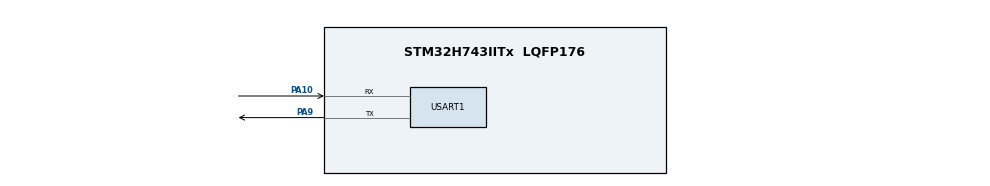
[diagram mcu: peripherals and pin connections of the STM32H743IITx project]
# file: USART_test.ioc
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Mcu.Family=STM32H7
Mcu.Name=STM32H743IITx
Mcu.Package=LQFP176
NVIC.PriorityGroup=NVIC_PRIORITYGROUP_4
NVIC.USART1_IRQn=true\:0\:0\:false\:false\:true\:true\:true
PA10.Mode=Asynchronous
PA10.Signal=USART1_RX
PA9.GPIO_Speed=GPIO_SPEED_FREQ_HIGH
PA9.Mode=Asynchronous
PA9.Signal=USART1_TX
PH0-OSC_IN\ (PH0).Mode=HSE-External-Oscillator
PH0-OSC_IN\ (PH0).Signal=RCC_OSC_IN
PH1-OSC_OUT\ (PH1).Mode=HSE-External-Oscillator
PH1-OSC_OUT\ (PH1).Signal=RCC_OSC_OUT
ProjectManager.HeapSize=0x200
ProjectManager.StackSize=0x400
ProjectManager.TargetToolchain=MDK-ARM V5.27
RCC.ADCFreq_Value=129000000
RCC.APB1Freq_Value=72000000
RCC.APB2Freq_Value=72000000
RCC.APB3Freq_Value=72000000
RCC.APB4Freq_Value=72000000
RCC.CortexFreq_Value=144000000
RCC.DIVM1=4
RCC.DIVN1=18
RCC.HCLKFreq_Value=72000000
RCC.HPRE=RCC_HCLK_DIV2
RCC.PLL2FRACN=0
RCC.PLL3FRACN=0
RCC.PLLFRACN=0
RCC.SYSCLKFreq_VALUE=144000000
RCC.SYSCLKSource=RCC_SYSCLKSOURCE_PLLCLK
RCC.USBFreq_Value=144000000
USART1.VirtualMode-Asynchronous=VM_ASYNC
board=custom

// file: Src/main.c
/* USER CODE BEGIN Header */
/**
  ******************************************************************************
  * @file           : main.c
  * @brief          : Main program body
  ******************************************************************************
  * @attention
  *
  * <h2><center>&copy; Copyright (c) 2020 STMicroelectronics.
  * All rights reserved.</center></h2>
  *
  * This software component is licensed by ST under BSD 3-Clause license,
  * the "License"; You may not use this file except in compliance with the
  * License. You may obtain a copy of the License at:
  *                        opensource.org/licenses/BSD-3-Clause
  *
  ******************************************************************************
  */
/* USER CODE END Header */

#include "main.h"
#include "usart.h"
#include "gpio.h"

/* USER CODE BEGIN PD */
//#define RX_MAX_COUNT           255  // 串口接收最大字节数

/* USER CODE END PD */

/* USER CODE BEGIN PV */
__IO uint8_t aRxBuffer; // 接收缓冲区
//__IO uint8_t aRxBuffer[RX_MAX_COUNT]={0}; //接收缓冲区
//__IO uint16_t usRxcount=0;                  // 已接收到的字节数
//__IO uint8_t Rxflag=0;                //接收标志位
/* USER CODE END PV */

void SystemClock_Config(void);

int main(void)
{
  /* USER CODE BEGIN 1 */
	uint8_t txbuf[100];//发送缓冲区

  /* USER CODE END 1 */

  /* MCU Configuration--------------------------------------------------------*/

  /* Reset of all peripherals, Initializes the Flash interface and the Systick. */
  HAL_Init();

  /* Configure the system clock */
  SystemClock_Config();

  /* Initialize all configured peripherals */
  MX_GPIO_Init();
  MX_USART1_UART_Init();
  /* USER CODE BEGIN 2 */
	memcpy(txbuf,"这是一个从STM32发送到电脑的数据\n",100);// 复制"这是一个从STM32发送到电脑的数据\n"到txbuf
	HAL_UART_Transmit(&huart1,txbuf,strlen((char *) txbuf),1000);// 串口发送函数
	HAL_Delay(1000);

	memcpy(txbuf,"hello world！man！\n",100);// 复制"hello world！man！\n"到txbuf ，100代表要发送的数据。
	HAL_UART_Transmit(&huart1,txbuf,strlen((char *) txbuf),1000);

	//使能接收中断
	HAL_UART_Receive_IT(&huart1,&aRxBuffer,1); //接收到一个数据就会产生中断

  /* USER CODE END 2 */

  /* Infinite loop */
  while (1)
  {

  }
}

//函数功能：串口接收完成回调函数
void HAL_UART_RxCpltCallback(UART_HandleTypeDef *UartHandle)
{

	HAL_UART_Transmit(&huart1,&aRxBuffer,1,0);//发送接收到的一个数据
	HAL_UART_Receive_IT(&huart1,&aRxBuffer,1);//使能重新接收一个数据

}

void SystemClock_Config(void)
{
  RCC_OscInitTypeDef RCC_OscInitStruct = {0};
  RCC_ClkInitTypeDef RCC_ClkInitStruct = {0};
  RCC_PeriphCLKInitTypeDef PeriphClkInitStruct = {0};

  /** Supply configuration update enable
  */
  HAL_PWREx_ConfigSupply(PWR_LDO_SUPPLY);
  /** Configure the main internal regulator output voltage
  */
  __HAL_PWR_VOLTAGESCALING_CONFIG(PWR_REGULATOR_VOLTAGE_SCALE3);

  while(!__HAL_PWR_GET_FLAG(PWR_FLAG_VOSRDY)) {}
  /** Initializes the CPU, AHB and APB busses clocks
  */
  RCC_OscInitStruct.OscillatorType = RCC_OSCILLATORTYPE_HSI;
  RCC_OscInitStruct.HSIState = RCC_HSI_DIV1;
  RCC_OscInitStruct.HSICalibrationValue = RCC_HSICALIBRATION_DEFAULT;
  RCC_OscInitStruct.PLL.PLLState = RCC_PLL_ON;
  RCC_OscInitStruct.PLL.PLLSource = RCC_PLLSOURCE_HSI;
  RCC_OscInitStruct.PLL.PLLM = 4;
  RCC_OscInitStruct.PLL.PLLN = 18;
  RCC_OscInitStruct.PLL.PLLP = 2;
  RCC_OscInitStruct.PLL.PLLQ = 2;
  RCC_OscInitStruct.PLL.PLLR = 2;
  RCC_OscInitStruct.PLL.PLLRGE = RCC_PLL1VCIRANGE_3;
  RCC_OscInitStruct.PLL.PLLVCOSEL = RCC_PLL1VCOWIDE;
  RCC_OscInitStruct.PLL.PLLFRACN = 0;
  if (HAL_RCC_OscConfig(&RCC_OscInitStruct) != HAL_OK)
  {
    Error_Handler();
  }
  /** Initializes the CPU, AHB and APB busses clocks
  */
  RCC_ClkInitStruct.ClockType = RCC_CLOCKTYPE_HCLK|RCC_CLOCKTYPE_SYSCLK
                              |RCC_CLOCKTYPE_PCLK1|RCC_CLOCKTYPE_PCLK2
                              |RCC_CLOCKTYPE_D3PCLK1|RCC_CLOCKTYPE_D1PCLK1;
  RCC_ClkInitStruct.SYSCLKSource = RCC_SYSCLKSOURCE_PLLCLK;
  RCC_ClkInitStruct.SYSCLKDivider = RCC_SYSCLK_DIV1;
  RCC_ClkInitStruct.AHBCLKDivider = RCC_HCLK_DIV2;
  RCC_ClkInitStruct.APB3CLKDivider = RCC_APB3_DIV1;
  RCC_ClkInitStruct.APB1CLKDivider = RCC_APB1_DIV1;
  RCC_ClkInitStruct.APB2CLKDivider = RCC_APB2_DIV1;
  RCC_ClkInitStruct.APB4CLKDivider = RCC_APB4_DIV1;

  if (HAL_RCC_ClockConfig(&RCC_ClkInitStruct, FLASH_LATENCY_1) != HAL_OK)
  {
    Error_Handler();
  }
  PeriphClkInitStruct.PeriphClockSelection = RCC_PERIPHCLK_USART1;
  PeriphClkInitStruct.Usart16ClockSelection = RCC_USART16CLKSOURCE_D2PCLK2;
  if (HAL_RCCEx_PeriphCLKConfig(&PeriphClkInitStruct) != HAL_OK)
  {
    Error_Handler();
  }
}

void Error_Handler(void)
{
}

/************************ (C) COPYRIGHT STMicroelectronics *****END OF FILE****/
